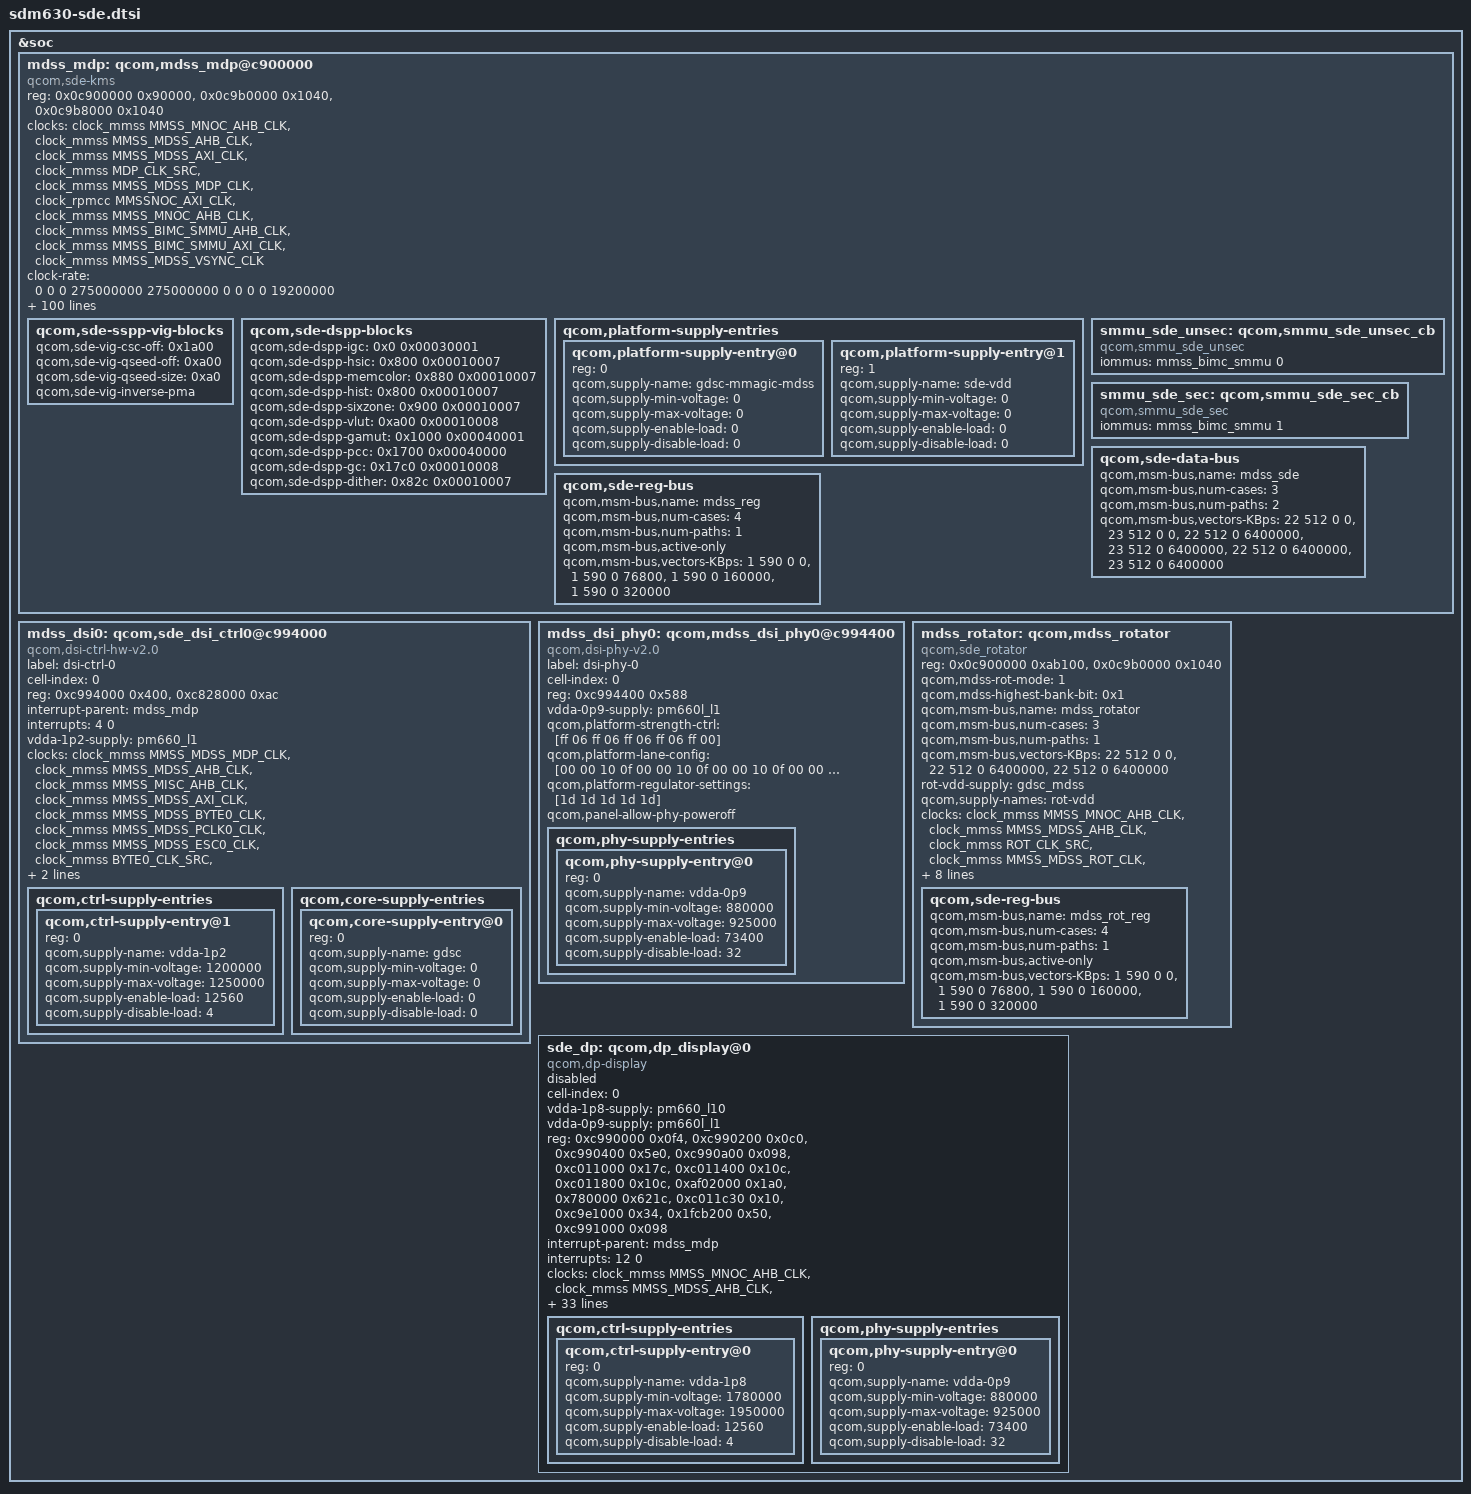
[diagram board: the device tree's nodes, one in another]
/*
 * Copyright (c) 2017-2018, The Linux Foundation. All rights reserved.
 * Copyright (c) 2019, Pavel Dubrova <pashadubrova@gmail.com>
 *
 * This program is free software; you can redistribute it and/or modify
 * it under the terms of the GNU General Public License version 2 and
 * only version 2 as published by the Free Software Foundation.
 *
 * This program is distributed in the hope that it will be useful,
 * but WITHOUT ANY WARRANTY; without even the implied warranty of
 * MERCHANTABILITY or FITNESS FOR A PARTICULAR PURPOSE.  See the
 * GNU General Public License for more details.
 */

#include <dt-bindings/clock/mdss-14nm-pll-clk.h>

&soc {
	mdss_mdp: qcom,mdss_mdp@c900000 {
		compatible = "qcom,sde-kms";
		reg = <0x0c900000 0x90000>,
		      <0x0c9b0000 0x1040>,
		      <0x0c9b8000 0x1040>;
		reg-names = "mdp_phys",
			"vbif_phys",
			"vbif_nrt_phys";

		clocks =
			<&clock_mmss MMSS_MNOC_AHB_CLK>,
			<&clock_mmss MMSS_MDSS_AHB_CLK>,
			<&clock_mmss MMSS_MDSS_AXI_CLK>,
			<&clock_mmss MDP_CLK_SRC>,
			<&clock_mmss MMSS_MDSS_MDP_CLK>,
			<&clock_rpmcc MMSSNOC_AXI_CLK>,
			<&clock_mmss MMSS_MNOC_AHB_CLK>,
			<&clock_mmss MMSS_BIMC_SMMU_AHB_CLK>,
			<&clock_mmss MMSS_BIMC_SMMU_AXI_CLK>,
			<&clock_mmss MMSS_MDSS_VSYNC_CLK>;
		clock-names = "mnoc_clk",
			"iface_clk",
			"bus_clk",
			"core_clk_src",
			"core_clk",
			"mmss_noc_axi_clk",
			"mmss_noc_ahb_clk",
			"mmss_smmu_ahb_clk",
			"mmss_smmu_axi_clk",
			"vsync_clk";
		clock-rate = <0 0 0 275000000 275000000 0 0 0 0 19200000>;
		clock-max-rate = <0 0 0  412500000 412500000 0 0 0 0 19200000>;

		gdsc-mmagic-mdss-supply = <&gdsc_bimc_smmu>;
		sde-vdd-supply = <&gdsc_mdss>;

		/* interrupt config */
		interrupt-parent = <&intc>;
		interrupts = <0 83 0>;
		interrupt-controller;
		#interrupt-cells = <1>;
		iommus = <&mmss_bimc_smmu 0>;

		#address-cells = <1>;
		#size-cells = <0>;

		#power-domain-cells = <0>;

		/* hw blocks */
		qcom,sde-off = <0x1000>;
		qcom,sde-len = <0x458>;

		qcom,sde-ctl-off = <0x2000 0x2200 0x2400
				     0x2600 0x2800>;
		qcom,sde-ctl-size = <0x94>;
		qcom,sde-ctl-display-pref = "primary", "none", "none",
						"none", "none";

		qcom,sde-mixer-off = <0x45000 0x47000>;
		qcom,sde-mixer-size = <0x2bc>;
		qcom,sde-mixer-display-pref = "primary", "none", "none",
						"none", "none", "none";

		qcom,sde-dspp-top-off = <0x1300>;
		qcom,sde-dspp-top-size = <0xc>;
		qcom,sde-dspp-off = <0x55000>;
		qcom,sde-dspp-size = <0x22c>;

		qcom,sde-wb-off = <0x66000>;
		qcom,sde-wb-size = <0x2c0>;
		qcom,sde-wb-xin-id = <6>;
		qcom,sde-wb-id = <2>;
		qcom,sde-wb-clk-ctrl = <0x2bc 24>;

		qcom,sde-intf-off = <0x6b000 0x6b800>;
		qcom,sde-intf-size = <0x268>;
		qcom,sde-intf-type = "dp", "dsi";

		qcom,sde-pp-off = <0x71000 0x72000 0x73000>;
		qcom,sde-pp-slave = <0x0 0x0 0x1>;
		qcom,sde-pp-size = <0x0d4>;

		qcom,sde-te-off = <0x0 0x0 0x0>;
		qcom,sde-te2-off = <0x2000 0x2000 0x0>;
		qcom,sde-te-source = <15 15 15>;

		qcom,sde-cdm-off = <0x7a200>;
		qcom,sde-cdm-size = <0x224>;

		qcom,sde-dither-off = <0x30e0 0x30e0 0x0>;
		qcom,sde-dither-version = <0x00010000>;
		qcom,sde-dither-size = <0x20>;

		qcom,sde-sspp-type = "vig", "dma", "dma", "dma", "cursor";

		qcom,sde-sspp-off = <0x5000 0x25000 0x27000 0x29000 0x35000>;
		qcom,sde-sspp-src-size = <0x184>;

		qcom,sde-sspp-xin-id = <0 1 5 9 2>;

		qcom,sde-mixer-pair-mask = <2 1>;
		qcom,sde-mixer-blend-op-off = <0x20 0x50 0x80 0xb0
						0x230 0x260 0x290>;

		/* offsets are relative to "mdp_phys + qcom,sde-off */
		qcom,sde-sspp-clk-ctrl = <0x2ac 0>, <0x2ac 8>, <0x2b4 8>,
					 <0x2c4 8>, <0x3a8 16>;
		qcom,sde-sspp-csc-off = <0x1a00>;
		qcom,sde-csc-type = "csc-10bit";
		qcom,sde-qseed-type = "qseedv3";
		qcom,sde-sspp-qseed-off = <0xa00>;
		qcom,sde-mixer-linewidth = <2560>;
		qcom,sde-sspp-linewidth = <2160>;
		qcom,sde-wb-linewidth = <2160>;
		qcom,sde-mixer-blendstages = <0x7>;
		qcom,sde-highest-bank-bit = <0x1>;
		qcom,sde-ubwc-version = <0x200>;
		qcom,sde-panic-per-pipe;
		qcom,sde-has-cdp;

		qcom,sde-has-dim-layer;
		qcom,sde-has-idle-pc;

		qcom,sde-max-bw-low-kbps = <6400000>;
		qcom,sde-max-bw-high-kbps = <6400000>;
		qcom,sde-min-core-ib-kbps = <2400000>;
		qcom,sde-min-llcc-ib-kbps = <800000>;
		qcom,sde-min-dram-ib-kbps = <800000>;
		qcom,sde-dram-channels = <2>;
		qcom,sde-num-nrt-paths = <1>;

		qcom,sde-vbif-off = <0>;
		qcom,sde-vbif-size = <0x1040>;
		qcom,sde-vbif-id = <0>;

		qcom,sde-vbif-qos-rt-remap = <1 2 2 2>;
		qcom,sde-vbif-qos-nrt-remap = <1 1 1 1>;

		/* macrotile & macrotile-qseed has the same configs */
		qcom,sde-danger-lut = <0x0000000f 0x0000ffff
			0x00000000 0x00000000>;

		qcom,sde-safe-lut-linear = <0 0xfffc>;
		qcom,sde-safe-lut-macrotile = <0 0xff00>;
		/* same as safe-lut-macrotile */
		qcom,sde-safe-lut-macrotile-qseed = <0 0xff00>;
		qcom,sde-safe-lut-nrt = <0 0xffff>;
		qcom,sde-safe-lut-cwb = <0 0xffff>;

		qcom,sde-qos-lut-linear = <0 0x00112222 0x22223357>;
		qcom,sde-qos-lut-macrotile = <0 0x00112233 0x44556677>;
		qcom,sde-qos-lut-macrotile-qseed = <0 0x00112233 0x66777777>;
		qcom,sde-qos-lut-nrt = <0 0x00000000 0x00000000>;
		qcom,sde-qos-lut-cwb = <0 0x75300000 0x00000000>;

		qcom,sde-cdp-setting = <1 1>, <1 0>;

		qcom,sde-qos-cpu-mask = <0x3>;
		qcom,sde-qos-cpu-dma-latency = <300>;

		/* offsets are relative to "mdp_phys + qcom,sde-off */
		qcom,sde-reg-dma-off = <0>;
		qcom,sde-reg-dma-version = <0x00010001>;
		qcom,sde-reg-dma-trigger-off = <0x119c>;

		qcom,sde-secure-sid-mask = <0x0000801>;

		qcom,sde-sspp-vig-blocks {
			qcom,sde-vig-csc-off = <0x1a00>;
			qcom,sde-vig-qseed-off = <0xa00>;
			qcom,sde-vig-qseed-size = <0xa0>;
			qcom,sde-vig-inverse-pma;
		};

		qcom,sde-dspp-blocks {
			qcom,sde-dspp-igc = <0x0 0x00030001>;
			qcom,sde-dspp-hsic = <0x800 0x00010007>;
			qcom,sde-dspp-memcolor = <0x880 0x00010007>;
			qcom,sde-dspp-hist = <0x800 0x00010007>;
			qcom,sde-dspp-sixzone= <0x900 0x00010007>;
			qcom,sde-dspp-vlut = <0xa00 0x00010008>;
			qcom,sde-dspp-gamut = <0x1000 0x00040001>;
			qcom,sde-dspp-pcc = <0x1700 0x00040000>;
			qcom,sde-dspp-gc = <0x17c0 0x00010008>;
			qcom,sde-dspp-dither = <0x82c 0x00010007>;
		};

		qcom,platform-supply-entries {
			#address-cells = <1>;
			#size-cells = <0>;

			qcom,platform-supply-entry@0 {
				reg = <0>;
				qcom,supply-name = "gdsc-mmagic-mdss";
				qcom,supply-min-voltage = <0>;
				qcom,supply-max-voltage = <0>;
				qcom,supply-enable-load = <0>;
				qcom,supply-disable-load = <0>;
			};

			qcom,platform-supply-entry@1 {
				reg = <1>;
				qcom,supply-name = "sde-vdd";
				qcom,supply-min-voltage = <0>;
				qcom,supply-max-voltage = <0>;
				qcom,supply-enable-load = <0>;
				qcom,supply-disable-load = <0>;
			};
		};

		smmu_sde_unsec: qcom,smmu_sde_unsec_cb {
			compatible = "qcom,smmu_sde_unsec";
			iommus = <&mmss_bimc_smmu 0>;
		};

		smmu_sde_sec: qcom,smmu_sde_sec_cb {
			compatible = "qcom,smmu_sde_sec";
			iommus = <&mmss_bimc_smmu 1>;
		};

		/* data and reg bus scale settings */
		qcom,sde-data-bus {
			qcom,msm-bus,name = "mdss_sde";
			qcom,msm-bus,num-cases = <3>;
			qcom,msm-bus,num-paths = <2>;
			qcom,msm-bus,vectors-KBps =
				<22 512 0 0>, <23 512 0 0>,
				<22 512 0 6400000>, <23 512 0 6400000>,
				<22 512 0 6400000>, <23 512 0 6400000>;
		};

		qcom,sde-reg-bus {
			qcom,msm-bus,name = "mdss_reg";
			qcom,msm-bus,num-cases = <4>;
			qcom,msm-bus,num-paths = <1>;
			qcom,msm-bus,active-only;
			qcom,msm-bus,vectors-KBps =
				<1 590 0 0>,
				<1 590 0 76800>,
				<1 590 0 160000>,
				<1 590 0 320000>;
		};
	};

	mdss_dsi0: qcom,sde_dsi_ctrl0@c994000 {
		compatible = "qcom,dsi-ctrl-hw-v2.0";
		label = "dsi-ctrl-0";
		cell-index = <0>;
		reg =   <0xc994000 0x400>,
			<0xc828000 0xac>;
		reg-names = "dsi_ctrl", "mmss_misc";

		interrupt-parent = <&mdss_mdp>;
		interrupts = <4 0>;
		vdda-1p2-supply = <&pm660_l1>;

		clocks = <&clock_mmss MMSS_MDSS_MDP_CLK>,
			 <&clock_mmss MMSS_MDSS_AHB_CLK>,
			 <&clock_mmss MMSS_MISC_AHB_CLK>,
			 <&clock_mmss MMSS_MDSS_AXI_CLK>,
			 <&clock_mmss MMSS_MDSS_BYTE0_CLK>,
			 <&clock_mmss MMSS_MDSS_PCLK0_CLK>,
			 <&clock_mmss MMSS_MDSS_ESC0_CLK>,
			 <&clock_mmss BYTE0_CLK_SRC>,
			 <&clock_mmss PCLK0_CLK_SRC>,
			 <&clock_mmss MMSS_MDSS_BYTE0_INTF_CLK>;

		clock-names = "mdp_core_clk", "iface_clk",
			"core_mmss_clk", "bus_clk",
			"byte_clk", "pixel_clk", "esc_clk",
			"byte_clk_rcg", "pixel_clk_rcg",
			"byte_intf_clk";

		qcom,ctrl-supply-entries {
			#address-cells = <1>;
			#size-cells = <0>;

			qcom,ctrl-supply-entry@1 {
				reg = <0>;
				qcom,supply-name = "vdda-1p2";
				qcom,supply-min-voltage = <1200000>;
				qcom,supply-max-voltage = <1250000>;
				qcom,supply-enable-load = <12560>;
				qcom,supply-disable-load = <4>;
			};
		};

		qcom,core-supply-entries {
			#address-cells = <1>;
			#size-cells = <0>;

			qcom,core-supply-entry@0 {
				reg = <0>;
				qcom,supply-name = "gdsc";
				qcom,supply-min-voltage = <0>;
				qcom,supply-max-voltage = <0>;
				qcom,supply-enable-load = <0>;
				qcom,supply-disable-load = <0>;
			};
		};
	};

	mdss_dsi_phy0: qcom,mdss_dsi_phy0@c994400 {
		compatible = "qcom,dsi-phy-v2.0";
		label = "dsi-phy-0";
		cell-index = <0>;
		reg = <0xc994400 0x588>;
		reg-names = "dsi_phy";
		vdda-0p9-supply = <&pm660l_l1>;

		qcom,platform-strength-ctrl = [ff 06
						ff 06
						ff 06
						ff 06
						ff 00];
		qcom,platform-lane-config = [00 00 10 0f
					00 00 10 0f
					00 00 10 0f
					00 00 10 0f
					00 00 10 8f];
		qcom,platform-regulator-settings = [1d 1d 1d 1d 1d];
		qcom,panel-allow-phy-poweroff;

		qcom,phy-supply-entries {
			#address-cells = <1>;
			#size-cells = <0>;

			qcom,phy-supply-entry@0 {
				reg = <0>;
				qcom,supply-name = "vdda-0p9";
				qcom,supply-min-voltage = <880000>;
				qcom,supply-max-voltage = <925000>;
				qcom,supply-enable-load = <73400>;
				qcom,supply-disable-load = <32>;
			};
		};
	};

	mdss_rotator: qcom,mdss_rotator {
		compatible = "qcom,sde_rotator";
		reg = <0x0c900000 0xab100>,
		      <0x0c9b0000 0x1040>;
		reg-names = "mdp_phys",
			"rot_vbif_phys";

		#list-cells = <1>;

		qcom,mdss-rot-mode = <1>;
		qcom,mdss-highest-bank-bit = <0x1>;

		/* Bus Scale Settings */
		qcom,msm-bus,name = "mdss_rotator";
		qcom,msm-bus,num-cases = <3>;
		qcom,msm-bus,num-paths = <1>;
		qcom,msm-bus,vectors-KBps =
			<22 512 0 0>,
			<22 512 0 6400000>,
			<22 512 0 6400000>;

		rot-vdd-supply = <&gdsc_mdss>;
		qcom,supply-names = "rot-vdd";

		clocks = <&clock_mmss MMSS_MNOC_AHB_CLK>,
			<&clock_mmss MMSS_MDSS_AHB_CLK>,
			<&clock_mmss ROT_CLK_SRC>,
			<&clock_mmss MMSS_MDSS_ROT_CLK>,
			<&clock_mmss MMSS_MDSS_AXI_CLK>;
		clock-names = "mnoc_clk",
			"iface_clk", "rot_core_clk",
			"rot_clk", "axi_clk";

		interrupt-parent = <&mdss_mdp>;
		interrupts = <2 0>;

		power-domains = <&mdss_mdp>;

		/* VBIF QoS remapper settings*/
		qcom,mdss-rot-vbif-qos-setting = <1 1 1 1>;
		qcom,mdss-rot-xin-id = <14 15>;

		qcom,mdss-default-ot-rd-limit = <32>;
		qcom,mdss-default-ot-wr-limit = <32>;

		
		/* Reg Bus Scale Settings */
		qcom,sde-reg-bus {
			qcom,msm-bus,name = "mdss_rot_reg";
			qcom,msm-bus,num-cases = <4>;
			qcom,msm-bus,num-paths = <1>;
			qcom,msm-bus,active-only;
			qcom,msm-bus,vectors-KBps =
				<1 590 0 0>,
				<1 590 0 76800>,
				<1 590 0 160000>,
				<1 590 0 320000>;
		};
	};

	/* TODO: Pinctrl is not ready */
	sde_dp: qcom,dp_display@0{
		cell-index = <0>;
		compatible = "qcom,dp-display";
		status = "disabled";

		vdda-1p8-supply = <&pm660_l10>;
		vdda-0p9-supply = <&pm660l_l1>;

		reg = <0xc990000 0x0f4>,
			<0xc990200 0x0c0>,
			<0xc990400 0x5e0>,
			<0xc990a00 0x098>,
			<0xc011000 0x17c>,
			<0xc011400 0x10c>,
			<0xc011800 0x10c>,
			<0xaf02000 0x1a0>,
			<0x780000 0x621c>,
			<0xc011c30 0x10>,
			<0xc9e1000 0x34>,
			<0x1fcb200 0x50>,
			<0xc991000 0x098>;

		/* dp_ctrl: dp_ahb, dp_aux, dp_link, dp_p0 */
		reg-names = "dp_ahb", "dp_aux", "dp_link",
			"dp_p0", "dp_phy", "dp_ln_tx0", "dp_ln_tx1",
			"dp_mmss_cc", "qfprom_physical", "dp_pll",
			"hdcp_physical", "dp_tcsr","dp_p1";

		interrupt-parent = <&mdss_mdp>;
		interrupts = <12 0>;

		clocks = <&clock_mmss MMSS_MNOC_AHB_CLK>,
			 <&clock_mmss MMSS_MDSS_AHB_CLK>,
			 <&clock_mmss MMSS_MDSS_AXI_CLK>,
			 <&clock_mmss MMSS_MDSS_MDP_CLK>,
			 <&clock_mmss MMSS_MDSS_HDMI_DP_AHB_CLK>,
			 <&clock_mmss MMSS_MDSS_DP_AUX_CLK>,
			 <&clock_rpmcc RPM_LN_BB_CLK1>,
			 <&clock_gcc GCC_USB3_CLKREF_CLK>,
			 <&clock_gcc GCC_USB_PHY_CFG_AHB2PHY_CLK>,
			 <&clock_mmss MMSS_MDSS_DP_LINK_CLK>,
			 <&clock_mmss MMSS_MDSS_DP_LINK_INTF_CLK>,
			 <&clock_mmss MMSS_MDSS_DP_CRYPTO_CLK>,
			 <&clock_mmss MMSS_MDSS_DP_PIXEL_CLK>,
			 <&clock_mmss DP_PIXEL_CLK_SRC>,
			 <&mdss_dp_pll DP_PHY_PLL_VCO_DIV_CLK>;
		clock-names = "core_mnoc_clk", "core_iface_clk", "core_bus_clk",
			"core_mdp_core_clk", "core_alt_iface_clk",
			"core_aux_clk", "core_ref_clk_src", "core_ref_clk",
			"core_ahb_phy_clk", "ctrl_link_clk",
			"ctrl_link_iface_clk", "ctrl_crypto_clk",
			"ctrl_pixel_clk", "pixel_clk_rcg", "pixel_parent";

		qcom,phy-version = <0x200>;
		qcom,aux-cfg0-settings = [20 00];
		qcom,aux-cfg1-settings = [24 13 23 1d];
		qcom,aux-cfg2-settings = [28 00];
		qcom,aux-cfg3-settings = [2c 00];
		qcom,aux-cfg4-settings = [30 0a];
		qcom,aux-cfg5-settings = [34 28];
		qcom,aux-cfg6-settings = [38 0a];
		qcom,aux-cfg7-settings = [3c 03];
		qcom,aux-cfg8-settings = [40 b7];
		qcom,aux-cfg9-settings = [44 03];

		qcom,logical2physical-lane-map = [00 01 02 03];

		qcom,max-pclk-frequency-khz = <300000>;

		qcom,ext-disp = <&ext_disp>;

		qcom,mux-sel-gpio = <&tlmm 55 0>;
		qcom,usbplug-cc-gpio = <&tlmm 58 0>;

		pinctrl-names = "mdss_dp_active", "mdss_dp_sleep";
		pinctrl-0 = <&mdss_dp_aux_active &mdss_dp_usbplug_cc_active>;
		pinctrl-1 = <&mdss_dp_aux_suspend &mdss_dp_usbplug_cc_suspend>;

		qcom,ctrl-supply-entries {
			#address-cells = <1>;
			#size-cells = <0>;

			qcom,ctrl-supply-entry@0 {
				reg = <0>;
				qcom,supply-name = "vdda-1p8";
				qcom,supply-min-voltage = <1780000>;
				qcom,supply-max-voltage = <1950000>;
				qcom,supply-enable-load = <12560>;
				qcom,supply-disable-load = <4>;
			};
		};

		qcom,phy-supply-entries {
			#address-cells = <1>;
			#size-cells = <0>;

			qcom,phy-supply-entry@0 {
				reg = <0>;
				qcom,supply-name = "vdda-0p9";
				qcom,supply-min-voltage = <880000>;
				qcom,supply-max-voltage = <925000>;
				qcom,supply-enable-load = <73400>;
				qcom,supply-disable-load = <32>;
			};
		};
	};
};
